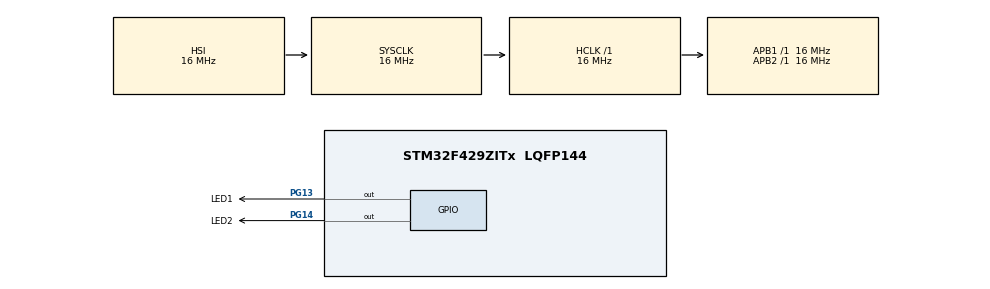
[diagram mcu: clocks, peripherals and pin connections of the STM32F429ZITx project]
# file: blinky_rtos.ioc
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FREERTOS.BinarySemaphores01=SEM1,Dynamic,NULL;SEM2,Dynamic,NULL
FREERTOS.Mutexes01=Mutex1,Dynamic,NULL
FREERTOS.Queues01=myQueue01,16,uint16_t,0,Dynamic,NULL,NULL
FREERTOS.Tasks01=defaultTask,0,128,StartDefaultTask,Default,NULL,Dynamic,NULL,NULL;LED_Thread1,2,128,StartTask02,Default,NULL,Dynamic,NULL,NULL;LED_Thread2,-1,128,StartTask03,Default,NULL,Dynamic,NULL,NULL
FREERTOS.Timers01=myTimer01,Callback01,osTimerPeriodic,Default,NULL,Dynamic,NULL
FREERTOS.configUSE_TIMERS=1
Mcu.Family=STM32F4
Mcu.Name=STM32F429ZITx
Mcu.Package=LQFP144
NVIC.PriorityGroup=NVIC_PRIORITYGROUP_4
NVIC.TIM1_UP_TIM10_IRQn=true\:0\:0\:false\:false\:true\:false\:false
NVIC.TimeBase=TIM1_UP_TIM10_IRQn
NVIC.TimeBaseIP=TIM1
PA13.Mode=Serial_Wire
PA13.Signal=SYS_JTMS-SWDIO
PA14.Mode=Serial_Wire
PA14.Signal=SYS_JTCK-SWCLK
PG13.GPIO_Label=LED1
PG13.Signal=GPIO_Output
PG14.GPIO_Label=LED2
PG14.Signal=GPIO_Output
ProjectManager.HeapSize=0x200
ProjectManager.StackSize=0x400
ProjectManager.TargetToolchain=SW4STM32
RCC.AHBFreq_Value=16000000
RCC.APB1Freq_Value=16000000
RCC.APB2Freq_Value=16000000
RCC.CortexFreq_Value=16000000
RCC.HSE_VALUE=25000000
RCC.HSI_VALUE=16000000
RCC.LSE_VALUE=32768
RCC.SYSCLKFreq_VALUE=16000000
RCC.VCOOutputFreq_Value=192000000
VP_FREERTOS_VS_ENABLE.Mode=Enabled
VP_SYS_VS_tim1.Mode=TIM1
board=custom

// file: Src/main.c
/**
  ******************************************************************************
  * @file           : main.c
  * @brief          : Main program body
  ******************************************************************************
  * This notice applies to any and all portions of this file
  * that are not between comment pairs USER CODE BEGIN and
  * USER CODE END. Other portions of this file, whether
  * inserted by the user or by software development tools
  * are owned by their respective copyright owners.
  *
  * Copyright (c) 2018 STMicroelectronics International N.V.
  * All rights reserved.
  *
  * Redistribution and use in source and binary forms, with or without
  * modification, are permitted, provided that the following conditions are met:
  *
  * 1. Redistribution of source code must retain the above copyright notice,
  *    this list of conditions and the following disclaimer.
  * 2. Redistributions in binary form must reproduce the above copyright notice,
  *    this list of conditions and the following disclaimer in the documentation
  *    and/or other materials provided with the distribution.
  * 3. Neither the name of STMicroelectronics nor the names of other
  *    contributors to this software may be used to endorse or promote products
  *    derived from this software without specific written permission.
  * 4. This software, including modifications and/or derivative works of this
  *    software, must execute solely and exclusively on microcontroller or
  *    microprocessor devices manufactured by or for STMicroelectronics.
  * 5. Redistribution and use of this software other than as permitted under
  *    this license is void and will automatically terminate your rights under
  *    this license.
  *
  * THIS SOFTWARE IS PROVIDED BY STMICROELECTRONICS AND CONTRIBUTORS "AS IS"
  * AND ANY EXPRESS, IMPLIED OR STATUTORY WARRANTIES, INCLUDING, BUT NOT
  * LIMITED TO, THE IMPLIED WARRANTIES OF MERCHANTABILITY, FITNESS FOR A
  * PARTICULAR PURPOSE AND NON-INFRINGEMENT OF THIRD PARTY INTELLECTUAL PROPERTY
  * RIGHTS ARE DISCLAIMED TO THE FULLEST EXTENT PERMITTED BY LAW. IN NO EVENT
  * SHALL STMICROELECTRONICS OR CONTRIBUTORS BE LIABLE FOR ANY DIRECT, INDIRECT,
  * INCIDENTAL, SPECIAL, EXEMPLARY, OR CONSEQUENTIAL DAMAGES (INCLUDING, BUT NOT
  * LIMITED TO, PROCUREMENT OF SUBSTITUTE GOODS OR SERVICES; LOSS OF USE, DATA,
  * OR PROFITS; OR BUSINESS INTERRUPTION) HOWEVER CAUSED AND ON ANY THEORY OF
  * LIABILITY, WHETHER IN CONTRACT, STRICT LIABILITY, OR TORT (INCLUDING
  * NEGLIGENCE OR OTHERWISE) ARISING IN ANY WAY OUT OF THE USE OF THIS SOFTWARE,
  * EVEN IF ADVISED OF THE POSSIBILITY OF SUCH DAMAGE.
  *
  ******************************************************************************
  */
#include "main.h"
#include "stm32f4xx_hal.h"
#include "cmsis_os.h"

/* USER CODE BEGIN Includes */
#include "freertos.h"
#include "stdio.h"
/* USER CODE END Includes */

osThreadId defaultTaskHandle;
osThreadId LED_Thread1Handle;
osThreadId LED_Thread2Handle;
osMessageQId myQueue01Handle;
osTimerId myTimer01Handle;
osMutexId Mutex1Handle;
osSemaphoreId SEM1Handle;
osSemaphoreId SEM2Handle;

/* USER CODE BEGIN PV */
/* Private variables ---------------------------------------------------------*/

/* USER CODE END PV */

void SystemClock_Config(void);
static void MX_GPIO_Init(void);
void StartDefaultTask(void const * argument);
void StartTask02(void const * argument);
void StartTask03(void const * argument);
void Callback01(void const * argument);

/* USER CODE BEGIN PFP */
/* Private function prototypes -----------------------------------------------*/
//extern void initialise_monitor_handles(void);
/* USER CODE END PFP */

int main(void)
{
  /* USER CODE BEGIN 1 */
	//initialise_monitor_handles();
	//printf("asdffa\n");
  /* USER CODE END 1 */

  /* MCU Configuration----------------------------------------------------------*/

  /* Reset of all peripherals, Initializes the Flash interface and the Systick. */
  HAL_Init();

  /* Configure the system clock */
  SystemClock_Config();

  /* Initialize all configured peripherals */
  MX_GPIO_Init();

  /* Create the mutex(es) */
  /* definition and creation of Mutex1 */
  osMutexDef(Mutex1);
  Mutex1Handle = osMutexCreate(osMutex(Mutex1));

  /* USER CODE BEGIN RTOS_MUTEX */
//  /* add mutexes, ... */
  /* USER CODE END RTOS_MUTEX */

  /* Create the semaphores(s) */
  /* definition and creation of SEM1 */
  osSemaphoreDef(SEM1);
  SEM1Handle = osSemaphoreCreate(osSemaphore(SEM1), 1);

  /* definition and creation of SEM2 */
  osSemaphoreDef(SEM2);
  SEM2Handle = osSemaphoreCreate(osSemaphore(SEM2), 1);

  /* Create the timer(s) */
  /* definition and creation of myTimer01 */
  osTimerDef(myTimer01, Callback01);
  myTimer01Handle = osTimerCreate(osTimer(myTimer01), osTimerPeriodic, NULL);

  /* Create the thread(s) */
  /* definition and creation of defaultTask */
  osThreadDef(defaultTask, StartDefaultTask, osPriorityNormal, 0, 128);
  defaultTaskHandle = osThreadCreate(osThread(defaultTask), NULL);

  /* definition and creation of LED_Thread1 */
  osThreadDef(LED_Thread1, StartTask02, osPriorityHigh, 0, 128);
  LED_Thread1Handle = osThreadCreate(osThread(LED_Thread1), NULL);

  /* definition and creation of LED_Thread2 */
  osThreadDef(LED_Thread2, StartTask03, osPriorityBelowNormal, 0, 128);
  LED_Thread2Handle = osThreadCreate(osThread(LED_Thread2), NULL);

  /* Create the queue(s) */
  /* definition and creation of myQueue01 */
/* what about the sizeof here??? cd native code */
  osMessageQDef(myQueue01, 16, uint16_t);
  myQueue01Handle = osMessageCreate(osMessageQ(myQueue01), NULL);

  /* Start scheduler */
  osKernelStart();

  /* We should never get here as control is now taken by the scheduler */

  /* Infinite loop */
  /* USER CODE BEGIN WHILE */
	/* --- APPLICATION TASKS CAN BE CREATED HERE --- */

	/* Start the created tasks running. */
//vTaskStartScheduler();

	/* Execution will only reach here if there was insufficient heap to
	start the scheduler. */
  while (1)
  {

  /* USER CODE END WHILE */

  }

}

void SystemClock_Config(void)
{

  RCC_OscInitTypeDef RCC_OscInitStruct;
  RCC_ClkInitTypeDef RCC_ClkInitStruct;

    /**Configure the main internal regulator output voltage
    */
  __HAL_RCC_PWR_CLK_ENABLE();

  __HAL_PWR_VOLTAGESCALING_CONFIG(PWR_REGULATOR_VOLTAGE_SCALE3);

    /**Initializes the CPU, AHB and APB busses clocks
    */
  RCC_OscInitStruct.OscillatorType = RCC_OSCILLATORTYPE_HSI;
  RCC_OscInitStruct.HSIState = RCC_HSI_ON;
  RCC_OscInitStruct.HSICalibrationValue = 16;
  RCC_OscInitStruct.PLL.PLLState = RCC_PLL_NONE;
  if (HAL_RCC_OscConfig(&RCC_OscInitStruct) != HAL_OK)
  {
    _Error_Handler(__FILE__, __LINE__);
  }

    /**Initializes the CPU, AHB and APB busses clocks
    */
  RCC_ClkInitStruct.ClockType = RCC_CLOCKTYPE_HCLK|RCC_CLOCKTYPE_SYSCLK
                              |RCC_CLOCKTYPE_PCLK1|RCC_CLOCKTYPE_PCLK2;
  RCC_ClkInitStruct.SYSCLKSource = RCC_SYSCLKSOURCE_HSI;
  RCC_ClkInitStruct.AHBCLKDivider = RCC_SYSCLK_DIV1;
  RCC_ClkInitStruct.APB1CLKDivider = RCC_HCLK_DIV1;
  RCC_ClkInitStruct.APB2CLKDivider = RCC_HCLK_DIV1;

  if (HAL_RCC_ClockConfig(&RCC_ClkInitStruct, FLASH_LATENCY_0) != HAL_OK)
  {
    _Error_Handler(__FILE__, __LINE__);
  }

    /**Configure the Systick interrupt time
    */
  HAL_SYSTICK_Config(HAL_RCC_GetHCLKFreq()/1000);

    /**Configure the Systick
    */
  HAL_SYSTICK_CLKSourceConfig(SYSTICK_CLKSOURCE_HCLK);

  /* SysTick_IRQn interrupt configuration */
  HAL_NVIC_SetPriority(SysTick_IRQn, 15, 0);
}

/** Configure pins as
        * Analog
        * Input
        * Output
        * EVENT_OUT
        * EXTI
*/
static void MX_GPIO_Init(void)
{

  GPIO_InitTypeDef GPIO_InitStruct;

  /* GPIO Ports Clock Enable */
  __HAL_RCC_GPIOA_CLK_ENABLE();
  __HAL_RCC_GPIOG_CLK_ENABLE();

  /*Configure GPIO pin Output Level */
  HAL_GPIO_WritePin(GPIOG, LED1_Pin|LED2_Pin, GPIO_PIN_RESET);

  /*Configure GPIO pins : LED1_Pin LED2_Pin */
  GPIO_InitStruct.Pin = LED1_Pin|LED2_Pin;
  GPIO_InitStruct.Mode = GPIO_MODE_OUTPUT_PP;
  GPIO_InitStruct.Pull = GPIO_NOPULL;
  GPIO_InitStruct.Speed = GPIO_SPEED_FREQ_LOW;
  HAL_GPIO_Init(GPIOG, &GPIO_InitStruct);

}

/* StartDefaultTask function */
void StartDefaultTask(void const * argument)
{

  for(;;)
  {
    osDelay(1);
  }
}

/* StartTask02 function */
void StartTask02(void const * argument)
{
  /* USER CODE BEGIN StartTask02 */
  /* Infinite loop */
//  volatile osStatus status = osMutexWait(Mutex1Handle, 10000);
  for(;;)
  {
	 osMutexWait (Mutex1Handle,0);
	 HAL_GPIO_WritePin(LED2_GPIO_Port, LED2_Pin,1);
//	 volatile osStatus m =osMessagePut (myQueue01Handle, 520,0 );
	 osDelay(5000);
	 osMutexRelease (Mutex1Handle);
	 osDelay(500);
  }
//  osMutexRelease(Mutex1Handle);
//volatile osStatus m =osMessagePut (myQueue01Handle, 1,0 );
	//vTaskDelete(NULL);
  /* USER CODE END StartTask02 */
}

/* StartTask03 function */
void StartTask03(void const * argument)
{
  /* USER CODE BEGIN StartTask03 */
  /* Infinite loop */
//  osMutexWait(Mutex1Handle, 8000);
	  for(;;)
	  {
		osMutexWait (Mutex1Handle,0);
		HAL_GPIO_WritePin(LED2_GPIO_Port, LED2_Pin,0);
//		volatile osStatus m =osMessagePut (myQueue01Handle, 520,0 );
		osDelay(5000);
		osMutexRelease (Mutex1Handle);
		osDelay(500);
	  }
//  volatile osStatus status = osMutexRelease(Mutex1Handle);
  //volatile int i;
  //volatile osEvent x=osMessageGet (myQueue01Handle,500 );
//	vTaskDelete(NULL);
  /* USER CODE END StartTask03 */
}

/* Callback01 function */
void Callback01(void const * argument)
{
  /* USER CODE BEGIN Callback01 */
  HAL_GPIO_TogglePin(LED1_GPIO_Port,LED1_Pin);
  /* USER CODE END Callback01 */
}

void HAL_TIM_PeriodElapsedCallback(TIM_HandleTypeDef *htim)
{
  if (htim->Instance == TIM1) {
    HAL_IncTick();
  }
}

void _Error_Handler(char *file, int line)
{
  while(1)
  {
  }
}

/************************ (C) COPYRIGHT STMicroelectronics *****END OF FILE****/
